# STM32F20x register map
File version: 1.0
Registers are 32-bit, read-write, reset 0x0 unless marked. A register's access mark holds for its fields unless they carry their own. Offsets are from the block's base; [hi:lo] are bit positions.

## I2C3 — Inter-integrated circuit
Base 0x40005C00
Same registers: I2C1 0x40005400, I2C2 0x40005800
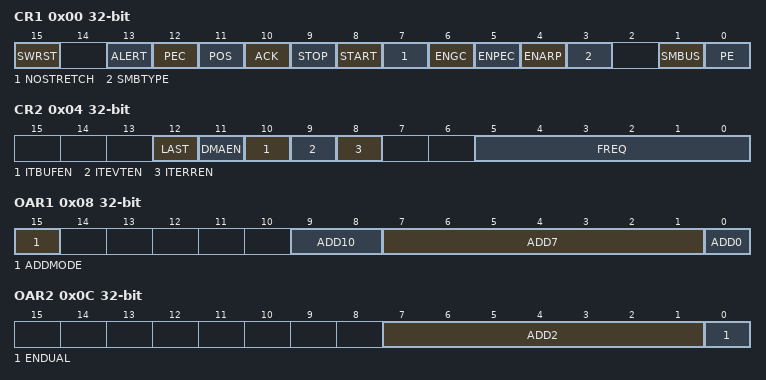
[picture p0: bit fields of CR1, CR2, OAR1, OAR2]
0x00 CR1 — Control register 1
  [15] SWRST — Software reset
  [13] ALERT — SMBus alert
  [12] PEC — Packet error checking
  [11] POS — Acknowledge/PEC Position (for data reception)
  [10] ACK — Acknowledge enable
  [9] STOP — Stop generation
  [8] START — Start generation
  [7] NOSTRETCH — Clock stretching disable (Slave mode)
  [6] ENGC — General call enable
  [5] ENPEC — PEC enable
  [4] ENARP — ARP enable
  [3] SMBTYPE — SMBus type
  [1] SMBUS — SMBus mode
  [0] PE — Peripheral enable
0x04 CR2 — Control register 2
  [12] LAST — DMA last transfer
  [11] DMAEN — DMA requests enable
  [10] ITBUFEN — Buffer interrupt enable
  [9] ITEVTEN — Event interrupt enable
  [8] ITERREN — Error interrupt enable
  [5:0] FREQ — Peripheral clock frequency
0x08 OAR1 — Own address register 1
  [15] ADDMODE — Addressing mode (slave mode)
  [9:8] ADD10 — Interface address
  [7:1] ADD7 — Interface address
  [0] ADD0 — Interface address
0x0C OAR2 — Own address register 2
  [7:1] ADD2 — Interface address
  [0] ENDUAL — Dual addressing mode enable
0x10 DR — Data register
  [7:0] DR — 8-bit data register
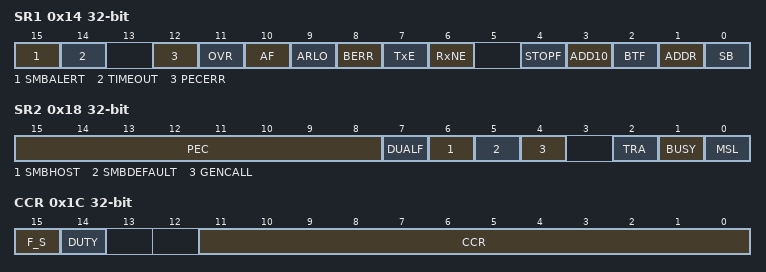
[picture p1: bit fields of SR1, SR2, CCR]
0x14 SR1 access per field — Status register 1
  [15] SMBALERT rw — SMBus alert
  [14] TIMEOUT rw — Timeout or Tlow error
  [12] PECERR rw — PEC Error in reception
  [11] OVR rw — Overrun/Underrun
  [10] AF rw — Acknowledge failure
  [9] ARLO rw — Arbitration lost (master mode)
  [8] BERR rw — Bus error
  [7] TxE ro — Data register empty (transmitters)
  [6] RxNE ro — Data register not empty (receivers)
  [4] STOPF ro — Stop detection (slave mode)
  [3] ADD10 ro — 10-bit header sent (Master mode)
  [2] BTF ro — Byte transfer finished
  [1] ADDR ro — Address sent (master mode)/matched (slave mode)
  [0] SB ro — Start bit (Master mode)
0x18 SR2 ro — Status register 2
  [15:8] PEC — acket error checking register
  [7] DUALF — Dual flag (Slave mode)
  [6] SMBHOST — SMBus host header (Slave mode)
  [5] SMBDEFAULT — SMBus device default address (Slave mode)
  [4] GENCALL — General call address (Slave mode)
  [2] TRA — Transmitter/receiver
  [1] BUSY — Bus busy
  [0] MSL — Master/slave
0x1C CCR — Clock control register
  [15] F_S — I2C master mode selection
  [14] DUTY — Fast mode duty cycle
  [11:0] CCR — Clock control register in Fast/Standard mode (Master mode)
0x20 TRISE reset 0x2
  [5:0] TRISE — Maximum rise time in Fast/Standard mode (Master mode)

## IWDG — Independent watchdog
Base 0x40003000
0x00 KR wo — Key register
  [15:0] KEY — Key value (write only, read 0000h)
0x04 PR — Prescaler register
  [2:0] PR — Prescaler divider
0x08 RLR reset 0xFFF — Reload register
  [11:0] RL — Watchdog counter reload value
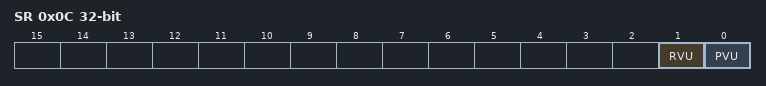
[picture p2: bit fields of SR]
0x0C SR ro — Status register
  [1] RVU — Watchdog counter reload value update
  [0] PVU — Watchdog prescaler value update

## WWDG — Window watchdog
Base 0x40002C00
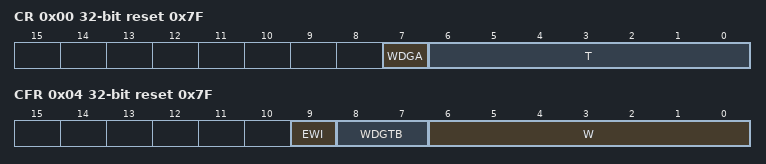
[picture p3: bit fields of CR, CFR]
0x00 CR reset 0x7F — Control register
  [7] WDGA — Activation bit
  [6:0] T — 7-bit counter (MSB to LSB)
0x04 CFR reset 0x7F — Configuration register
  [9] EWI — Early wakeup interrupt
  [8:7] WDGTB — Timer base
  [6:0] W — 7-bit window value
0x08 SR — Status register
  [0] EWIF — Early wakeup interrupt flag

## UART4 — Universal synchronous asynchronous receiver transmitter
Base 0x40004C00
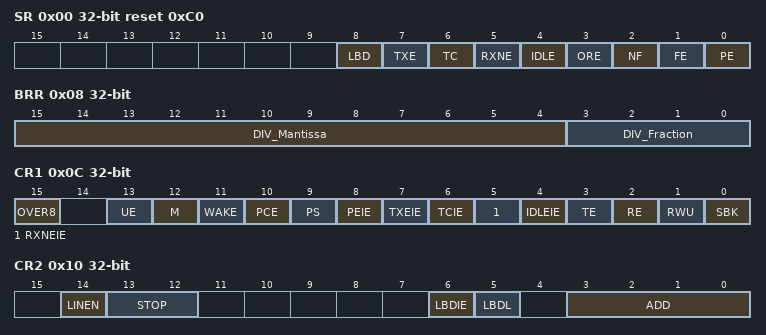
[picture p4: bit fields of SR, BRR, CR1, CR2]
0x00 SR access per field reset 0xC0 — Status register
  [8] LBD rw — LIN break detection flag
  [7] TXE ro — Transmit data register empty
  [6] TC rw — Transmission complete
  [5] RXNE rw — Read data register not empty
  [4] IDLE ro — IDLE line detected
  [3] ORE ro — Overrun error
  [2] NF ro — Noise detected flag
  [1] FE ro — Framing error
  [0] PE ro — Parity error
0x04 DR — Data register
  [8:0] DR — Data value
0x08 BRR — Baud rate register
  [15:4] DIV_Mantissa — mantissa of USARTDIV
  [3:0] DIV_Fraction — fraction of USARTDIV
0x0C CR1 — Control register 1
  [15] OVER8 — Oversampling mode
  [13] UE — USART enable
  [12] M — Word length
  [11] WAKE — Wakeup method
  [10] PCE — Parity control enable
  [9] PS — Parity selection
  [8] PEIE — PE interrupt enable
  [7] TXEIE — TXE interrupt enable
  [6] TCIE — Transmission complete interrupt enable
  [5] RXNEIE — RXNE interrupt enable
  [4] IDLEIE — IDLE interrupt enable
  [3] TE — Transmitter enable
  [2] RE — Receiver enable
  [1] RWU — Receiver wakeup
  [0] SBK — Send break
0x10 CR2 — Control register 2
  [14] LINEN — LIN mode enable
  [13:12] STOP — STOP bits
  [6] LBDIE — LIN break detection interrupt enable
  [5] LBDL — lin break detection length
  [3:0] ADD — Address of the USART node
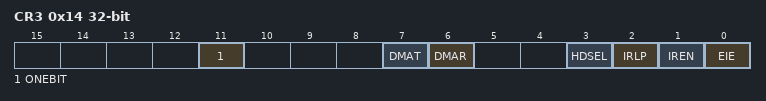
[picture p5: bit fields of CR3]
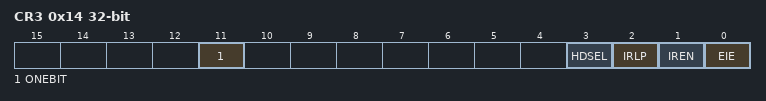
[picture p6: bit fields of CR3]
0x14 CR3 — Control register 3
  [11] ONEBIT — One sample bit method enable
  [7] DMAT — DMA enable transmitter
  [6] DMAR — DMA enable receiver
  [3] HDSEL — Half-duplex selection
  [2] IRLP — IrDA low-power
  [1] IREN — IrDA mode enable
  [0] EIE — Error interrupt enable

## UART5 — Universal synchronous asynchronous receiver transmitter
Base 0x40005000
Registers as UART4; these are added or differ:
0x14 CR3 — Control register 3
  [11] ONEBIT — One sample bit method enable
  [3] HDSEL — Half-duplex selection
  [2] IRLP — IrDA low-power
  [1] IREN — IrDA mode enable
  [0] EIE — Error interrupt enable
